# LPC11E6x register map
File version: 0.8
CPU: CM0PLUS r0p1, little endian, no MPU, no FPU, 0x2 interrupt priority bits, 0x0 interrupts
Registers are 32-bit, read-write, reset 0x0 unless marked. A register's access mark holds for its fields unless they carry their own. Offsets are from the block's base; [hi:lo] are bit positions; {n}, {i} and the like mark numbered series.

## DMATRIGMUX — DMA controller
Base 0x40028000
{0x0+4i} DMA_ITRIG_PINMUX[{i}] reset 0x1F (i=0..15) — Trigger input select register for DMA channel 0.
  [4:0] INP_N — Trigger input number (decimal value) to DMA channel n. All other values are reserved. 0 = ADC0_SEQA_IRQ 1 = ADC0_SEQB_IRQ 2 = CT16B0_MAT0 3 = CT16B1_MAT0 4 = CT32B0_MAT0 5 = CT16B1_MAT0 6 = PINT0 ( pin interrupt 0) 7 = PINT1 (pin interrupt1 ) 8 = SCT0_DMA0 9 = SCT0_DMA1 10 = SCT1_DMA0 11 = SCT1_DMA1

## PMU — Power Management Unit (PMU)
Base 0x40038000
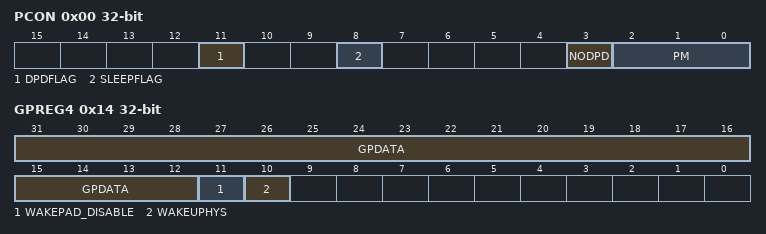
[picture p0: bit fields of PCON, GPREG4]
0x00 PCON — Power control register
  [11] DPDFLAG — Deep power-down flag
    0=NOT_DEEP_POWER_DOWN (Not Deep power-down. Read: Deep power-down mode not entered. Write: No effect.); 1=DEEP_POWER_DOWN (Deep power-down. Read: Deep power-down mode entered. Write: Clear the Deep power-down flag.)
  [8] SLEEPFLAG — Sleep mode flag
    0=ACTIVE_MODE (Active mode. Read: No power-down mode entered. Part is in Active mode. Write: No effect.); 1=LOW_POWER_MODE (Low power mode. Read: Sleep/Deep-sleep or Deep power-down mode entered. Write: Writing a 1 clears the SLEEPFLAG bit to 0.)
  [3] NODPD — A 1 in this bit prevents entry to Deep power-down mode when 0x3 is written to the PM field above, the SLEEPDEEP bit is set, and a WFI is executed. This bit is cleared only by power-on reset, so writing a one to this bit locks the part in a mode in which Deep power-down mode is blocked.
  [2:0] PM — Power mode
    0=DEFAULT (Default. The part is in active or sleep mode.); 1=DEEP_SLEEP (Deep-sleep. ARM WFI will enter Deep-sleep mode.); 2=POWER_DOWN (Power-down. ARM WFI will enter Power-down mode.); 3=DEEP_POWER_DOWN (Deep power-down. ARM WFI will enter Deep-power down mode (ARM Cortex-M0+ core powered-down).)
{0x4+4i} GPREG{i} (i=0..3) — General purpose register 0
  [31:0] GPDATA — Data retained during Deep power-down mode.
0x14 GPREG4 — Deep power down control register
  [31:12] GPDATA — Data retained during Deep power-down mode.
  [11] WAKEPAD_DISABLE — WAKEUP pin disable. Setting this bit disables the wake-up pin, so it can be used for other purposes. Never set this bit if you intend to use a pin to wake up the part from Deep power-down mode. You can only disable the wake-up pin if the RTC wake-up timer is enabled and configured. Setting this bit is not necessary if Deep power-down mode is not used.
    0=ENABLE (Enable. The wake-up function is enabled on pin PIO0_16.); 1=DISABLE (Disable. Setting this bit disables the wake-up function on pin PIO0_16.)
  [10] WAKEUPHYS — WAKEUP pin hysteresis enable
    0=DISABLE_HYSTERESIS_F (Disable Hysteresis for WAKUP pin disabled.); 1=ENABLE (Enable. Hysteresis for WAKEUP pin enabled.)

## FLASHCTRL — Flash controller
Base 0x4003C000
0x10 FLASHCFG reset not defined — Flash configuration register
  [1:0] FLASHTIM — Flash memory access time. FLASHTIM +1 is equal to the number of system clocks used for flash access.
    0=1_SYSTEM_CLOCK_FLASH (1 system clock flash access time (for system clock frequencies of up to 20 MHz).); 1=2_SYSTEM_CLOCKS_FLAS (2 system clocks flash access time (for system clock frequencies of up to 30 MHz).)
0x20 FMSSTART — Signature start address register
  [16:0] START — Signature generation start address (corresponds to AHB byte address bits[20:4]).
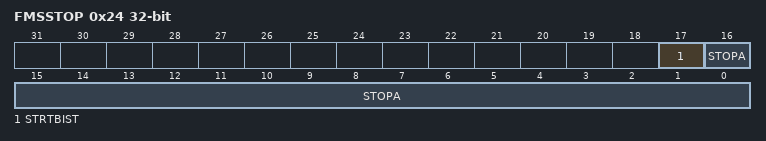
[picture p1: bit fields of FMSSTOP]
0x24 FMSSTOP — Signature stop-address register
  [17] STRTBIST — When this bit is written to 1, signature generation starts. At the end of signature generation, this bit is automatically cleared.
  [16:0] STOPA — Stop address for signature generation (the word specified by STOPA is included in the address range). The address is in units of memory words, not bytes. If the option bistprotection=1, bits 2:0 cannot be written and are forced to 111.
0x2C FMSW0 ro reset not defined — Signature Word
  [31:0] SIG — 32-bit signature.
